# CY8C4247LTI_M475 register map
File version: 0.1
PSoC 4200M
Registers are 32-bit, read-write, no defined reset value unless marked. A register's access mark holds for its fields unless they carry their own. Offsets are from the block's base; lines under a group give offsets from that group; [hi:lo] are bit positions; {n}, {i} and the like mark numbered series; 'fields as' and 'values as' point back to an identical list; <NAME> marks a mode.

## Memory map
0x00000000 Control_Trig
0x00000000 IDAC_2 — IDAC
0x00000000 DMAC — DMAC Registers
0x00000000 EZI2C — Serial Communication Block
0x00000000 Comp_1 — Comparator
0x00000000 TIMER
0x00000000 IDAC_1 — IDAC
0x00000000 Opamp_FACE — OpAmp
0x00000000 ADC — Sequencing SAR ADC
0x00000000 Opamp_2 — OpAmp
0x00000000 PWM_CHARGE
0x00000000 Opamp_1 — OpAmp

## Control_Trig
Base 0x00000000
0x400F0070 Control_Trig_CONTROL_REG 8-bit

## IDAC_2 — IDAC
Base 0x00000000
0x40290004 CSD_IDAC_POLARITY
0x40290008 CSD_IDAC
0x4029FF00 CSD_TRIM1 — CSD IDAC TRIM1
0x4029FF04 CSD_TRIM2 — CSD IDAC TRIM2

## Comp_1 — Comparator
Base 0x00000000
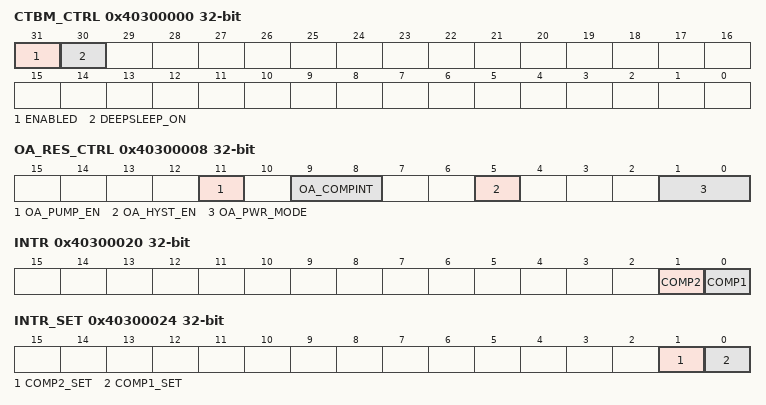
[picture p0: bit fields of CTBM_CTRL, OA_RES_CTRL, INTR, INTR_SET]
0x40300000 CTBM_CTRL — Global CTB IP and power control
  [31] ENABLED — Selects component behavior in DeepSleep power mode
    0=DISABLE (CTB IP disabled (put analog in power down, open all switches)); 1=ENABLE (CTB IP enabledCTB IP enabled)
  [30] DEEPSLEEP_ON — Selects component behavior in DeepSleep power mode
    0=DISABLE (CTB IP disabled off during DeepSleep power mode); 1=ENABLE (CTB IP remains enabled during DeepSleep power mode (if ENABLED=1))
0x40300008 OA_RES_CTRL — Comparator and resistor control
  [11] OA_PUMP_EN — Selects pump
    0=DISABLE (Pump disabled); 1=ENABLE (Pump enabled)
  [9:8] OA_COMPINT — Selects comparator edge detect
    0=DISABLE (Disabled); 1=RISING (Rising edge); 2=FALLING (Falling edge); 3=BOTH (Both rising and falling edges)
  [5] OA_HYST_EN — Selects hysteresis (10mV)
    0=DISABLE (Hysteresis disabled); 1=ENABLE (Hysteresis enabled)
  [1:0] OA_PWR_MODE — Selects speed for comparator
    0=OFF; 1=SLOW (Slow speed); 2=MED (Medium speed); 3=FAST (Fast speed)
0x4030000C COMP_STAT — Comparator status
  [16] OA_COMP ro — Current comparator status
0x40300020 INTR — Interrupt request register
  [1] COMP2 — Comparator #2 Interrupt: hardware sets this interrupt when comparator 0 triggers. Write with '1' to clear bit.
  [0] COMP1 — Comparator #1 Interrupt: hardware sets this interrupt when comparator 0 triggers. Write with '1' to clear bit.
0x40300024 INTR_SET — Interrupt request set register
  [1] COMP2_SET — Write with '1' to set corresponding bit in interrupt request register.
  [0] COMP1_SET — Write with '1' to set corresponding bit in interrupt request register.
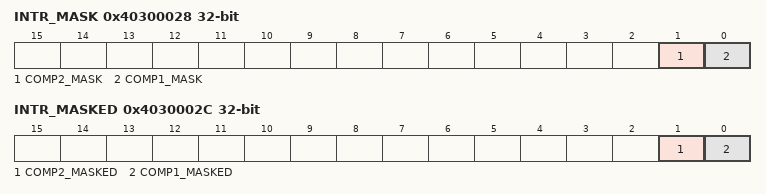
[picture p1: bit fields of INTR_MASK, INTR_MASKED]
0x40300028 INTR_MASK — Interrupt request mask
  [1] COMP2_MASK — Mask bit for corresponding bit in interrupt request register.
  [0] COMP1_MASK — Mask bit for corresponding bit in interrupt request register.
0x4030002C INTR_MASKED — Interrupt request masked
  [1] COMP2_MASKED ro — Logical and of corresponding request and mask bits.
  [0] COMP1_MASKED ro — Logical and of corresponding request and mask bits.
0x40300F0C OA_OFFSET_TRIM — Comparator offset trim
0x40300F10 OA_SLOPE_OFFSET_TRIM — Comparator slope offset drift trim
0x40300F14 OA_COMP_TRIM — Comparator trim

## TIMER
Base 0x00000000
0x40200148 COUNTER — Current counter value
0x4020014C CC — Compare / capture value
0x40200150 CC_BUF — Compare / capture buffer value
0x40200154 PERIOD — Period value
0x40200158 PERIOD_BUF — Period buffer value

## IDAC_1 — IDAC
Base 0x00000000
0x40280004 CSD_IDAC_POLARITY
0x40280008 CSD_IDAC
0x4028FF00 CSD_TRIM1 — CSD IDAC TRIM1
0x4028FF04 CSD_TRIM2 — CSD IDAC TRIM2

## Opamp_FACE — OpAmp
Base 0x00000000
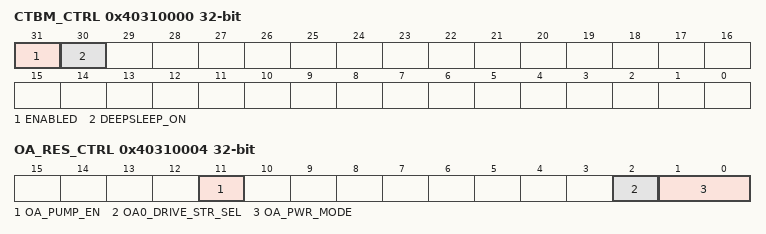
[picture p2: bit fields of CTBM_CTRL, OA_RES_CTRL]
0x40310000 CTBM_CTRL — Global CTB IP and power control
  [31] ENABLED — Selects component behavior in DeepSleep power mode
    0=DISABLE (CTB IP disabled (put analog in power down, open all switches)); 1=ENABLE (CTB IP enabledCTB IP enabled)
  [30] DEEPSLEEP_ON — Selects component behavior in DeepSleep power mode
    0=DISABLE (CTB IP disabled off during DeepSleep power mode); 1=ENABLE (CTB IP remains enabled during DeepSleep power mode (if ENABLED=1))
0x40310004 OA_RES_CTRL — Opamp and resistor control
  [11] OA_PUMP_EN — Selects pump
    0=DISABLE (Pump disabled); 1=ENABLE (Pump enabled)
  [2] OA0_DRIVE_STR_SEL — Opamp output strenght select
    0=Cy1x (Internal only); 1=Cy10x (Output to pin)
  [1:0] OA_PWR_MODE — Selects power for opamp
    0=OFF; 1=LOW (Low power); 2=MED (Medium power); 3=HIGH (High power)
0x40310F08 OA_COMP_TRIM — Opamp Compenation Capacitor Trim
  [1:0] OA_COMP_TRIM
    1=HIGH_SPEED; 2=BALANCED; 3=HIGH_STABILITY
